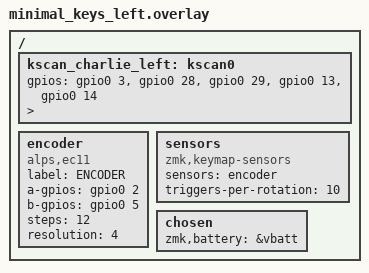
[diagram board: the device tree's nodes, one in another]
#include "minimal_keys.dtsi"

/ {
    kscan_charlie_left: kscan0 {
        gpios = < &gpio0 3 GPIO_ACTIVE_HIGH >,         // 使用するGPIOピン列（例）
                < &gpio0 28 GPIO_ACTIVE_HIGH >,
                < &gpio0 29 GPIO_ACTIVE_HIGH >,
                < &gpio0 13 GPIO_ACTIVE_HIGH >,
                < &gpio0 14 GPIO_ACTIVE_HIGH >;
                < &gpio0 15 GPIO_ACTIVE_HIGH >;
                < &gpio0 9 GPIO_ACTIVE_HIGH >;
                                    // スリープ解除ソースに指定
    };

    // ロータリーエンコーダー設定
    encoder: encoder {
        compatible = "alps,ec11";
        label = "ENCODER";
        a-gpios = <&gpio0 2 (GPIO_ACTIVE_HIGH | GPIO_PULL_UP)>;   // P0.05 (D5/A5)
        b-gpios = <&gpio0 5 (GPIO_ACTIVE_HIGH | GPIO_PULL_UP)>;   // P0.02 (D0/A0)
         steps = <12>;
        resolution = <4>;
    };

    sensors {
        compatible = "zmk,keymap-sensors";
        sensors = <&encoder>;
        triggers-per-rotation = <10>;
    };

    // バッテリー設定
    chosen {
        zmk,battery = &vbatt;
    };
};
